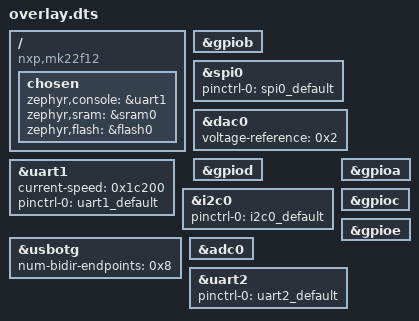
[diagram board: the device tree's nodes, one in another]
/ {
	compatible = "nxp,mk22f12", "nxp,k22f", "nxp,k2x";
	chosen {
		zephyr,console = &uart1;
		zephyr,sram = &sram0;
		zephyr,flash = &flash0;
	};
};
&gpiob{
	status = "okay";
};
&spi0{
	status = "okay";
	pinctrl-0 = < &spi0_default >;
	pinctrl-names = "default";
};
&dac0{
	voltage-reference = < 0x2 >;
	status = "okay";
};
&gpiod{
	status = "okay";
};
&uart1{
	status = "okay";
	current-speed = < 0x1c200 >;
	pinctrl-0 = < &uart1_default >;
	pinctrl-names = "default";
};
&i2c0{
	status = "okay";
	pinctrl-0 = < &i2c0_default >;
	pinctrl-names = "default";
};
&gpioa{
	status = "okay";
};
&gpioc{
	status = "okay";
};
&gpioe{
	status = "okay";
};
&usbotg{
	num-bidir-endpoints = < 0x8 >;
	status = "okay";
};
&adc0{
	status = "okay";
};
&uart2{
	pinctrl-0 = < &uart2_default >;
	pinctrl-names = "default";
};
